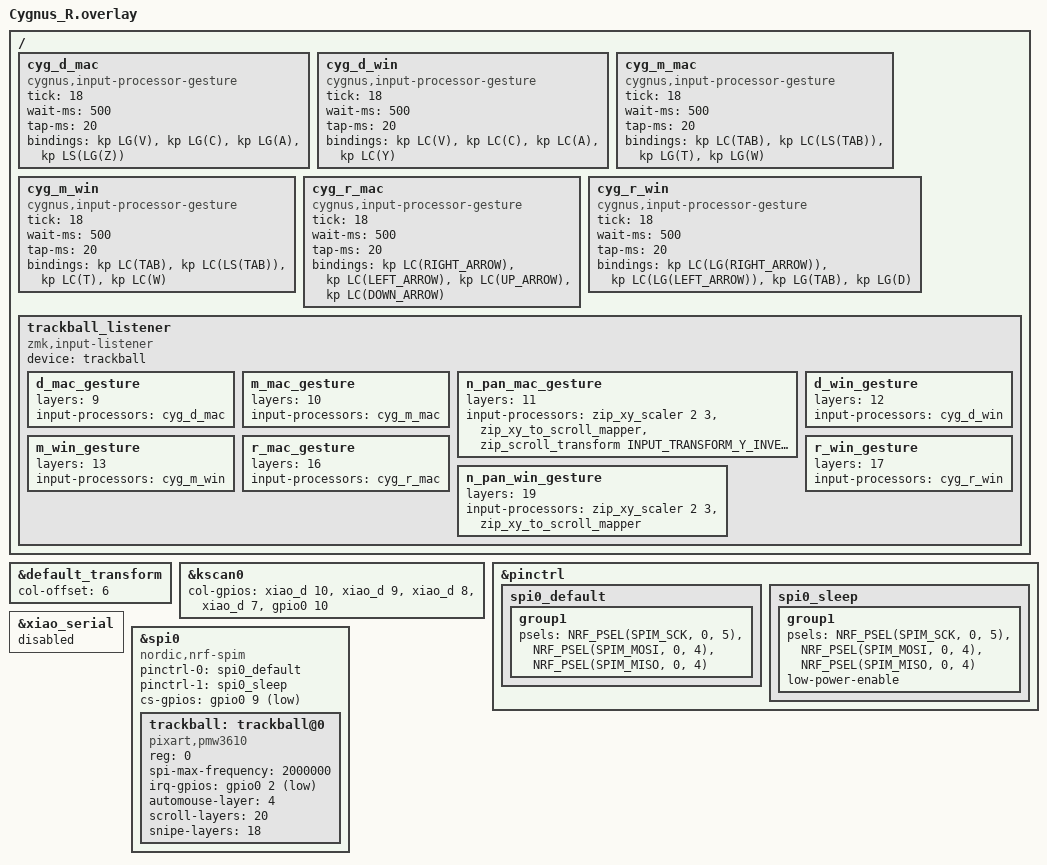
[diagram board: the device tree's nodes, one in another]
#include "Cygnus.dtsi"
#include <input/processors.dtsi>
#include <behaviors.dtsi>
#include <dt-bindings/zmk/input_transform.h>
#include <dt-bindings/zmk/keys.h>

&default_transform {
    col-offset = <6>;
};

&kscan0 {
        col-gpios
            = <&xiao_d 10 GPIO_ACTIVE_HIGH>
            , <&xiao_d 9 GPIO_ACTIVE_HIGH> 
            , <&xiao_d 8 GPIO_ACTIVE_HIGH> 
            , <&xiao_d 7 GPIO_ACTIVE_HIGH> 
            , <&gpio0 10 GPIO_ACTIVE_HIGH>
            ;
};

/ {
    cyg_d_mac: cyg_d_mac {
        compatible = "cygnus,input-processor-gesture";
        #input-processor-cells = <0>;
        tick = <18>;
        // Avoid repeated copy/paste/select firing during one held gesture.
        wait-ms = <500>;
        tap-ms = <20>;
        // Order required by src/cygnus_gesture_processor.c: right, left, up, down.
        bindings = <&kp LG(V) &kp LG(C) &kp LG(A) &kp LS(LG(Z))>;
    };

    cyg_d_win: cyg_d_win {
        compatible = "cygnus,input-processor-gesture";
        #input-processor-cells = <0>;
        tick = <18>;
        wait-ms = <500>;
        tap-ms = <20>;
        bindings = <&kp LC(V) &kp LC(C) &kp LC(A) &kp LC(Y)>;
    };

    cyg_m_mac: cyg_m_mac {
        compatible = "cygnus,input-processor-gesture";
        #input-processor-cells = <0>;
        tick = <18>;
        wait-ms = <500>;
        tap-ms = <20>;
        bindings = <&kp LC(TAB) &kp LC(LS(TAB)) &kp LG(T) &kp LG(W)>;
    };

    cyg_m_win: cyg_m_win {
        compatible = "cygnus,input-processor-gesture";
        #input-processor-cells = <0>;
        tick = <18>;
        wait-ms = <500>;
        tap-ms = <20>;
        bindings = <&kp LC(TAB) &kp LC(LS(TAB)) &kp LC(T) &kp LC(W)>;
    };

    cyg_r_mac: cyg_r_mac {
        compatible = "cygnus,input-processor-gesture";
        #input-processor-cells = <0>;
        tick = <18>;
        wait-ms = <500>;
        tap-ms = <20>;
        bindings = <&kp LC(RIGHT_ARROW) &kp LC(LEFT_ARROW) &kp LC(UP_ARROW) &kp LC(DOWN_ARROW)>;
    };

    cyg_r_win: cyg_r_win {
        compatible = "cygnus,input-processor-gesture";
        #input-processor-cells = <0>;
        tick = <18>;
        wait-ms = <500>;
        tap-ms = <20>;
        bindings = <&kp LC(LG(RIGHT_ARROW)) &kp LC(LG(LEFT_ARROW)) &kp LG(TAB) &kp LG(D)>;
    };

    trackball_listener {
        compatible = "zmk,input-listener";
        device = <&trackball>;

        d_mac_gesture {
            layers = <9>;
            input-processors = <&cyg_d_mac>;
        };

        m_mac_gesture {
            layers = <10>;
            input-processors = <&cyg_m_mac>;
        };

        n_pan_mac_gesture {
            layers = <11>;
            input-processors =
                <&zip_xy_scaler 2 3>,
                <&zip_xy_to_scroll_mapper>,
                <&zip_scroll_transform INPUT_TRANSFORM_Y_INVERT>;
        };

        d_win_gesture {
            layers = <12>;
            input-processors = <&cyg_d_win>;
        };

        m_win_gesture {
            layers = <13>;
            input-processors = <&cyg_m_win>;
        };

        r_mac_gesture {
            layers = <16>;
            input-processors = <&cyg_r_mac>;
        };

        r_win_gesture {
            layers = <17>;
            input-processors = <&cyg_r_win>;
        };

        n_pan_win_gesture {
            layers = <19>;
            input-processors =
                <&zip_xy_scaler 2 3>,
                <&zip_xy_to_scroll_mapper>;
        };
    };
};

&pinctrl {
    spi0_default: spi0_default {
        group1 {
            psels = <NRF_PSEL(SPIM_SCK, 0, 5)>,
                <NRF_PSEL(SPIM_MOSI, 0, 4)>,
                <NRF_PSEL(SPIM_MISO, 0, 4)>;
        };
    };

    spi0_sleep: spi0_sleep {
        group1 {
            psels = <NRF_PSEL(SPIM_SCK, 0, 5)>,
                <NRF_PSEL(SPIM_MOSI, 0, 4)>,
                <NRF_PSEL(SPIM_MISO, 0, 4)>;
            low-power-enable;
        };
    };
};

&xiao_serial { status = "disabled"; };

&spi0 {
    status = "okay";
    compatible = "nordic,nrf-spim";
    pinctrl-0 = <&spi0_default>;
    pinctrl-1 = <&spi0_sleep>;
    pinctrl-names = "default", "sleep";
    cs-gpios = <&gpio0 9 GPIO_ACTIVE_LOW>;

    trackball: trackball@0 {
        status = "okay";
        compatible = "pixart,pmw3610";
        reg = <0>;
        spi-max-frequency = <2000000>;
        irq-gpios = <&gpio0 2 (GPIO_ACTIVE_LOW | GPIO_PULL_UP)>;
        automouse-layer = <4>;
        scroll-layers = <20>;
        snipe-layers = <18>;
    };
};
